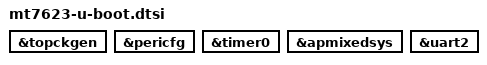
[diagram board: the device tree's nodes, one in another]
// SPDX-License-Identifier: GPL-2.0
/*
 * Copyright (c) 2019 MediaTek Inc.
 * Author: Sam Shih <sam.shih@mediatek.com>
 */

&topckgen {
	bootph-all;
};

&topckgen {
	bootph-all;
};

&pericfg {
	bootph-all;
};

&timer0 {
	bootph-all;
};

&apmixedsys {
	bootph-all;
};

&uart2 {
	bootph-all;
};
